# ESP32S31_RADIO register map
Vendor: Espressif; Series: ESP32-S31; File version: 3.52
Registers are 32-bit, read-write, no defined reset value unless marked. A register's access mark holds for its fields unless they carry their own. Offsets are from the block's base; [hi:lo] are bit positions; {n}, {i} and the like mark numbered series.

## HP_SYS_CLKRST_UART0 — HP system clock/reset registers: UART0's function clock, which the boot ROM prints through after a software reset.
Base 0x20587000
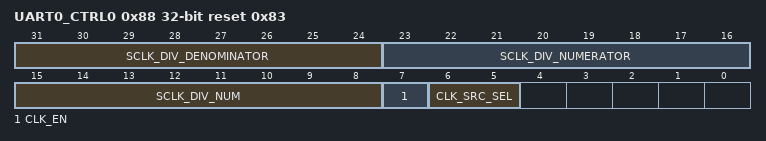
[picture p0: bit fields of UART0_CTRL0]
0x88 UART0_CTRL0 reset 0x83 — UART0's function clock: source, enable and divider. Its bus clock and reset bits are not described.
  [31:24] SCLK_DIV_DENOMINATOR — Denominator of the function clock divider's fractional part.
  [23:16] SCLK_DIV_NUMERATOR — Numerator of the function clock divider's fractional part.
  [15:8] SCLK_DIV_NUM — Integral part of the function clock divider; zero divides by one.
  [7] CLK_EN — Function clock enable.
  [6:5] CLK_SRC_SEL — Function clock source: 0 XTAL, 1 RC_FAST, 2 PLL_F80M.

## LP_AON_CLKRST_CORE_RESET — LP always-on clock/reset registers: the software CPU reset of each HP core. Their stall, reset-length and debug fields are not described.
Base 0x20701000
0x3C HPCORE0_RESET_CTRL reset 0x40010000 — HP core 0's reset control.
  [20] HPCORE0_SW_RESET wo — Writing one resets HP core 0 once; it does not hold the core in reset.
0x40 HPCORE1_RESET_CTRL reset 0x40010000 — HP core 1's reset control.
  [20] HPCORE1_SW_RESET wo — Writing one resets HP core 1 once; it does not hold the core in reset.

## WIFI_MAC_STA_BEACON_FILTER — Station beacon-filter control word recovered from the complete enable and disable leaves. The three low bits are toggled together; individual hardware meanings remain unknown.
Base 0x201042B4
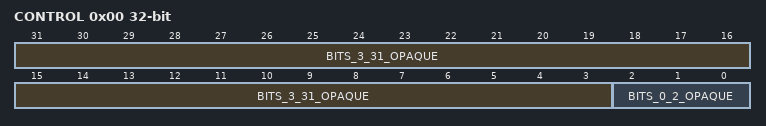
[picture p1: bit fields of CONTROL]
0x00 CONTROL — Project-assigned name. hal_enable_sta_beacon_filter sets bits 2:0 after enabling the matching interrupt; hal_disable_sta_beacon_filter clears them before disabling that interrupt.
  [31:3] BITS_3_31_OPAQUE — Opaque: meaning not established. Observed source use; the individual hardware meaning is unknown.
  [2:0] BITS_0_2_OPAQUE — Opaque: meaning not established.

## WIFI_MAC_BEACON_IE_CRC — Full beacon-IE CRC/result word returned through the caller output pointer by complete hal_beacon_ie_crc_get.
Base 0x20104300
0x00 RESULT ro — Project-assigned name.
  [31:0] VALUE

## WIFI_MAC_RX_END_STATE — Receive-end state word returned by the complete hal_mac_rx_get_end_state and hal_mac_rx_get_end_info leaves.
Base 0x201040A8
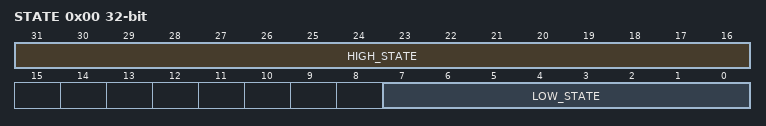
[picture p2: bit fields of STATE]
0x00 STATE ro — Project-assigned name. hal_mac_rx_get_end_info returns the low byte through its third output pointer; hal_mac_rx_get_end_state returns the high halfword. The middle byte remains unnamed.
  [31:16] HIGH_STATE — Project-assigned name.
  [7:0] LOW_STATE — Project-assigned name.

## WIFI_MAC_RX_RUNTIME_RESULTS — Sparse receive statistics-clear and end-result words recovered from complete hal_sniffer_rx_clr_statistics and hal_mac_rx_get_end_info leaves.
Base 0x20104E28
0x00 STATISTICS_CLEAR — Project-assigned name. Complete hal_sniffer_rx_clr_statistics pulses bit 31 high then low using a fresh read before each write.
  [31] CLEAR_PULSE — Project-assigned name.
0x08 END_RESULT_LOW ro — Project-assigned name. First full result word returned by hal_mac_rx_get_end_info.
  [31:0] VALUE — Project-assigned name.
0x0C END_RESULT_HIGH ro — Project-assigned name. Second full result word returned by hal_mac_rx_get_end_info.
  [31:0] VALUE — Project-assigned name.

## WIFI_MAC_BSSID_POLICY — Per-interface BSSID address and policy words used by scan and associated-STA receive filtering.
Base 0x20104000
{0x0+8i} BSSID_LOW{i} (i=0..3) — Project-assigned name. BSSID bytes 0..3 for interfaces 0..3; hal_mac_set_bssid publishes a complete full-word store.
  [31:0] BYTES_0_3 — Project-assigned name.
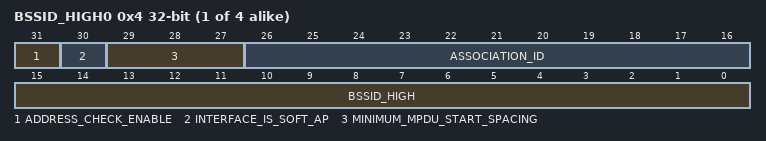
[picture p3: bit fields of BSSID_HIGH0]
{0x4+8i} BSSID_HIGH{i} (i=0..3) — Project-assigned name. Canonical high BSSID, association identity and interface policy word for interfaces 0..3. Complete dbg_read_rx_misc independently decodes every field; the HE association leaf updates the MMSS/AID fields of interface zero rather than defining a second register identity.
  [31] ADDRESS_CHECK_ENABLE — Project-assigned name. MACBSSID_EN: hal_mac_set_bssid clears this bit before changing the address and sets it after publication; the reachable associated-STA policy branch also sets it.
  [30] INTERFACE_IS_SOFT_AP — Project-assigned name. Cleared for interface zero by the associated-STA policy-five transaction.
  [29:27] MINIMUM_MPDU_START_SPACING — Project-assigned name. Three-bit MMSS value printed by dbg_read_rx_misc.
  [26:16] ASSOCIATION_ID — Project-assigned name. Eleven-bit AID printed by dbg_read_rx_misc.
  [15:0] BSSID_HIGH — Project-assigned name.
